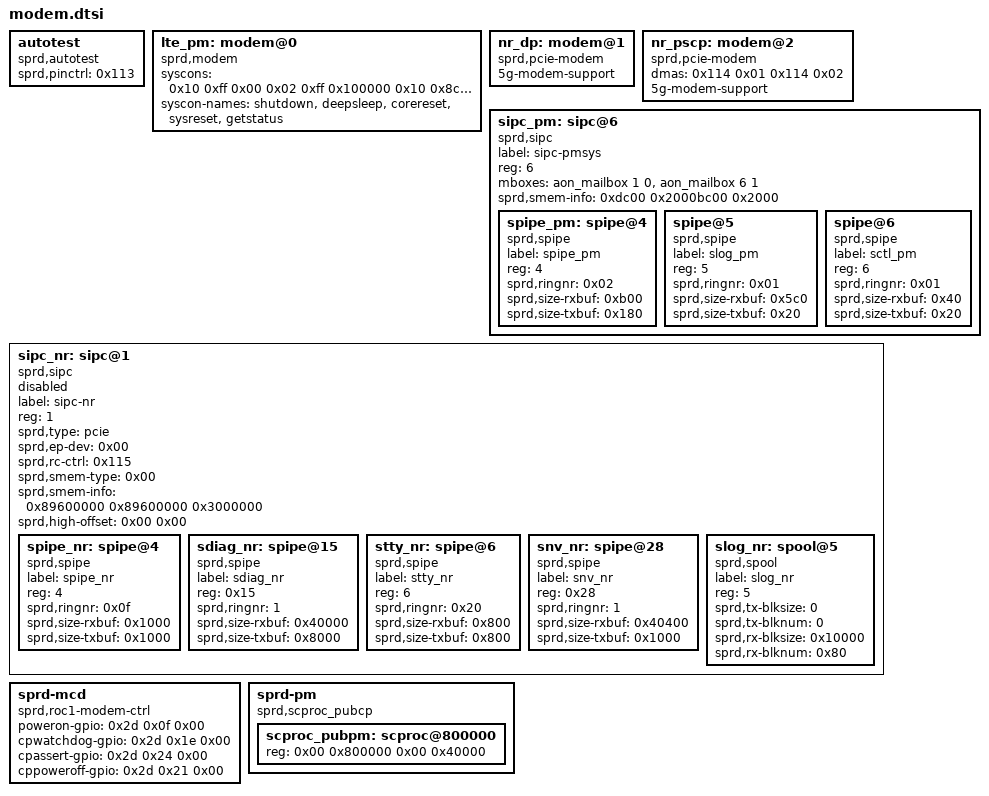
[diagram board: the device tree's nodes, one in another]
/*
 * istudy-c10 hardware description; included in place from the board DTS.
 * Copyright (C) 2026 Evarentha - Linux 5.15 board port changes.
 */

	autotest: autotest {
		compatible = "sprd,autotest";
		sprd,pinctrl = <0x113>;
		phandle = <0x1db>;
	};

	lte_pm: modem@0 {
		compatible = "sprd,modem";
		syscons = <0x10 0xff 0x00 0x02 0xff 0x100000 0x10 0x8c 0x01 0x10 0xff 0x00 0x10 0xff 0x00>;
		syscon-names = "shutdown", "deepsleep", "corereset", "sysreset", "getstatus";
		phandle = <0x1dc>;
	};

	nr_dp: modem@1 {
		compatible = "sprd,pcie-modem";
		5g-modem-support;
		phandle = <0x1dd>;
	};

	nr_pscp: modem@2 {
		compatible = "sprd,pcie-modem";
		dmas = <0x114 0x01 0x114 0x02>;
		dma-names = "mem_read", "mem_write";
		5g-modem-support;
		phandle = <0x1de>;
	};

	sipc_pm: sipc@6 {
		compatible = "sprd,sipc";
		label = "sipc-pmsys";
		reg = <6>;
		mboxes = <&aon_mailbox 1 0>, <&aon_mailbox 6 1>;
		sprd,smem-info = <0xdc00 0x2000bc00 0x2000>;
		phandle = <0x1df>;
		#address-cells = <1>;
		#size-cells = <0>;

		spipe_pm: spipe@4 {
			compatible = "sprd,spipe";
			label = "spipe_pm";
			reg = <4>;
			sprd,ringnr = <0x02>;
			sprd,size-rxbuf = <0xb00>;
			sprd,size-txbuf = <0x180>;
			phandle = <0x1e1>;
		};

		spipe@5 {
			compatible = "sprd,spipe";
			label = "slog_pm";
			reg = <5>;
			sprd,ringnr = <0x01>;
			sprd,size-rxbuf = <0x5c0>;
			sprd,size-txbuf = <0x20>;
		};

		spipe@6 {
			compatible = "sprd,spipe";
			label = "sctl_pm";
			reg = <6>;
			sprd,ringnr = <0x01>;
			sprd,size-rxbuf = <0x40>;
			sprd,size-txbuf = <0x20>;
		};
	};

	sipc_nr: sipc@1 {
		compatible = "sprd,sipc";
		label = "sipc-nr";
		reg = <1>;
		/* PCIe SIPC transport is not implemented by the 5.15 driver. */
		status = "disabled";
		sprd,type = "pcie";
		sprd,ep-dev = <0x00>;
		sprd,rc-ctrl = <0x115>;
		sprd,smem-type = <0x00>;
		sprd,smem-info = <0x89600000 0x89600000 0x3000000>;
		sprd,high-offset = <0x00 0x00>;
		phandle = <0x1e0>;
		#address-cells = <1>;
		#size-cells = <0>;

		spipe_nr: spipe@4 {
			compatible = "sprd,spipe";
			label = "spipe_nr";
			reg = <4>;
			sprd,ringnr = <0x0f>;
			sprd,size-rxbuf = <0x1000>;
			sprd,size-txbuf = <0x1000>;
			phandle = <0x1e2>;
		};

		sdiag_nr: spipe@15 {
			compatible = "sprd,spipe";
			label = "sdiag_nr";
			reg = <0x15>;
			sprd,ringnr = <1>;
			sprd,size-rxbuf = <0x40000>;
			sprd,size-txbuf = <0x8000>;
			phandle = <0x1e3>;
		};

		stty_nr: spipe@6 {
			compatible = "sprd,spipe";
			label = "stty_nr";
			reg = <6>;
			sprd,ringnr = <0x20>;
			sprd,size-rxbuf = <0x800>;
			sprd,size-txbuf = <0x800>;
			phandle = <0x1e4>;
		};

		snv_nr: spipe@28 {
			compatible = "sprd,spipe";
			label = "snv_nr";
			reg = <0x28>;
			sprd,ringnr = <1>;
			sprd,size-rxbuf = <0x40400>;
			sprd,size-txbuf = <0x1000>;
			phandle = <0x1e5>;
		};

		slog_nr: spool@5 {
			compatible = "sprd,spool";
			label = "slog_nr";
			reg = <5>;
			sprd,tx-blksize = <0>;
			sprd,tx-blknum = <0>;
			sprd,rx-blksize = <0x10000>;
			sprd,rx-blknum = <0x80>;
			phandle = <0x1e6>;
		};
	};

	sprd-mcd {
		compatible = "sprd,roc1-modem-ctrl";
		poweron-gpio = <0x2d 0x0f 0x00>;
		cpwatchdog-gpio = <0x2d 0x1e 0x00>;
		cpassert-gpio = <0x2d 0x24 0x00>;
		cppoweroff-gpio = <0x2d 0x21 0x00>;
	};

	sprd-pm {
		compatible = "sprd,scproc_pubcp";
		#address-cells = <0x02>;
		#size-cells = <0x02>;
		ranges;

		scproc_pubpm: scproc@800000 {
			reg = <0x00 0x800000 0x00 0x40000>;
			phandle = <0x124>;
		};
	};

